# M344 register map
File version: 2.0.2.6
Registers are 32-bit, read-write, reset 0x0 unless marked. A register's access mark holds for its fields unless they carry their own. Offsets are from the block's base; [hi:lo] are bit positions; {n}, {i} and the like mark numbered series.

## TD0A — Timer D (Unit0)
Base 0x40158000
Same registers: TD0B 0x40359000
0x00 RUN wo — Timer Run Register (Unit0)
  [0] TDRUN
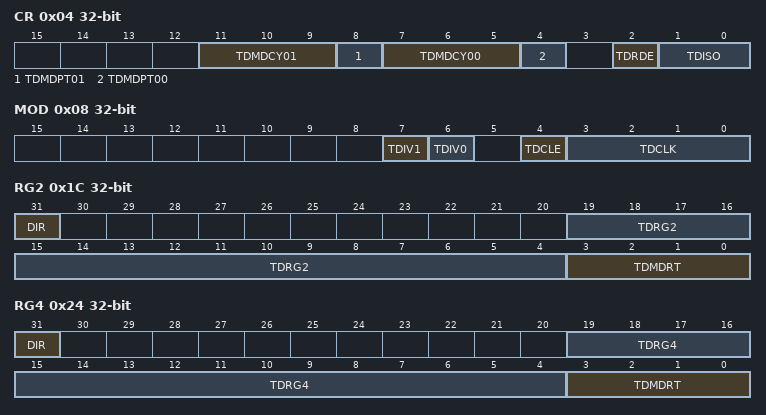
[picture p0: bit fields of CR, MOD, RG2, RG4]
0x04 CR — Timer Control Register (Unit0)
  [11:9] TDMDCY01, [8] TDMDPT01, [7:5] TDMDCY00, [4] TDMDPT00, [2] TDRDE, [1:0] TDISO
0x08 MOD — Timer Mode Register (Unit0)
  [7] TDIV1, [6] TDIV0, [4] TDCLE, [3:0] TDCLK
0x0C DMA — DMA Request Enable Register (Unit0)
  [0] DMAEN
0x14 RG0 — Timer Register0 (Unit0)
  [15:0] TDRG0
0x18 RG1 — Timer Register1 (Unit0)
  [15:0] TDRG1
0x1C RG2 — Timer Register2 (Unit0)
  [31] DIR, [19:4] TDRG2, [3:0] TDMDRT
0x20 RG3 — Timer Register3 (Unit0)
  [15:0] TDRG3
0x24 RG4 — Timer Register4 (Unit0)
  [31] DIR, [19:4] TDRG4, [3:0] TDMDRT
0x28 RG5 — Timer Register5 (Unit0)
  [16:1] TDRG5
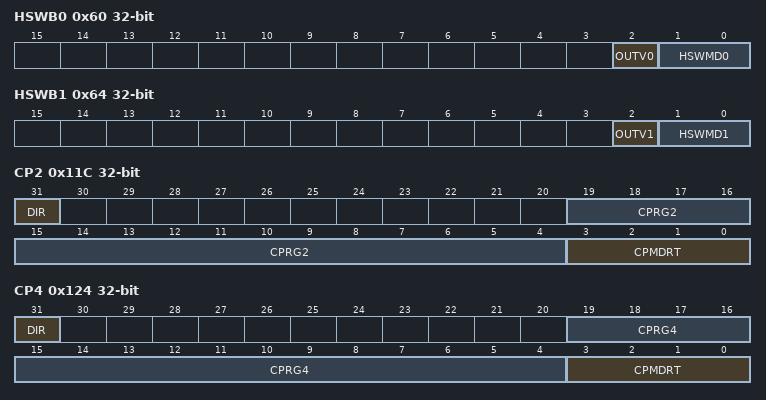
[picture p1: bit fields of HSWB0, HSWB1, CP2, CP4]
0x60 HSWB0 — H-SW Control Circuit Register Buffer0 (Unit0)
  [2] OUTV0, [1:0] HSWMD0
0x64 HSWB1 — H-SW Control Circuit Register Buffer1 (Unit0)
  [2] OUTV1, [1:0] HSWMD1
0x114 CP0 ro — Compare Register0 (Unit0)
  [15:0] CPRG0
0x118 CP1 ro — Compare Register1 (Unit0)
  [15:0] CPRG1
0x11C CP2 ro — Compare Register2 (Unit0)
  [31] DIR, [19:4] CPRG2, [3:0] CPMDRT
0x120 CP3 ro — Compare Register3 (Unit0)
  [15:0] CPRG3
0x124 CP4 ro — Compare Register4 (Unit0)
  [31] DIR, [19:4] CPRG4, [3:0] CPMDRT
0x128 CP5 ro — Compare Register5 (Unit0)
  [15:0] CPRG5
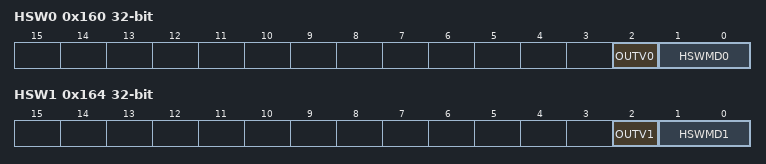
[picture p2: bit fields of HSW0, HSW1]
0x160 HSW0 ro — H-SW Control Circuit Register (Unit0)
  [2] OUTV0, [1:0] HSWMD0
0x164 HSW1 ro — H-SW Control Circuit Register (Unit0)
  [2] OUTV1, [1:0] HSWMD1

## TDA — Timer D common
Base 0x40158040
Same registers: TDB 0x40359040
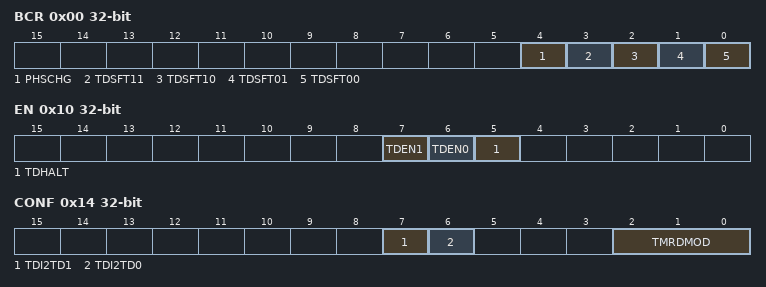
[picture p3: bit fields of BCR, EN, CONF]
0x00 BCR — Update Flag Setting Register
  [4] PHSCHG, [3] TDSFT11, [2] TDSFT10, [1] TDSFT01, [0] TDSFT00
0x10 EN — Timer Enable Register
  [7] TDEN1, [6] TDEN0, [5] TDHALT
0x14 CONF — Timer Configuration Register
  [7] TDI2TD1, [6] TDI2TD0, [2:0] TMRDMOD

## TD1A — Timer D (Unit1)
Base 0x4015802C
Same registers: TD1B 0x4035902C
0x00 RG0 — Timer Register0 (Unit1)
  [15:0] TDRG0
0x04 RG1 — Timer Register1 (Unit1)
  [15:0] TDRG1
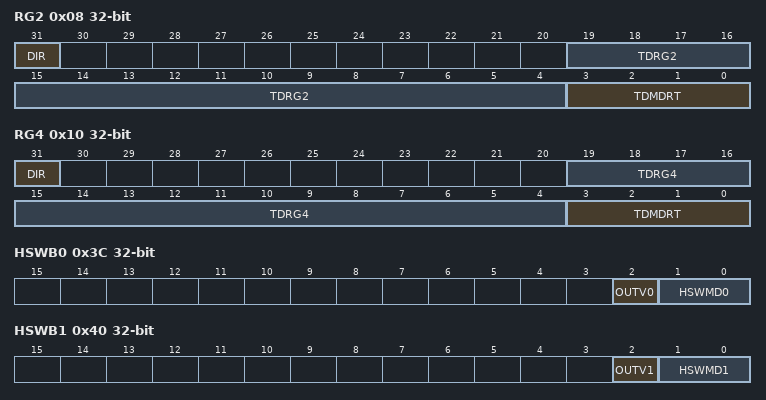
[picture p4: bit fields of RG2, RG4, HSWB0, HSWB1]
0x08 RG2 — Timer Register2 (Unit1)
  [31] DIR, [19:4] TDRG2, [3:0] TDMDRT
0x0C RG3 — Timer Register3 (Unit1)
  [15:0] TDRG3
0x10 RG4 — Timer Register4 (Unit1)
  [31] DIR, [19:4] TDRG4, [3:0] TDMDRT
0x3C HSWB0 — H-SW Control Circuit Register Buffer0 (Unit1)
  [2] OUTV0, [1:0] HSWMD0
0x40 HSWB1 — H-SW Control Circuit Register Buffer1 (Unit1)
  [2] OUTV1, [1:0] HSWMD1
0xD4 RUN wo — Timer Run Register (Unit1)
  [0] TDRUN
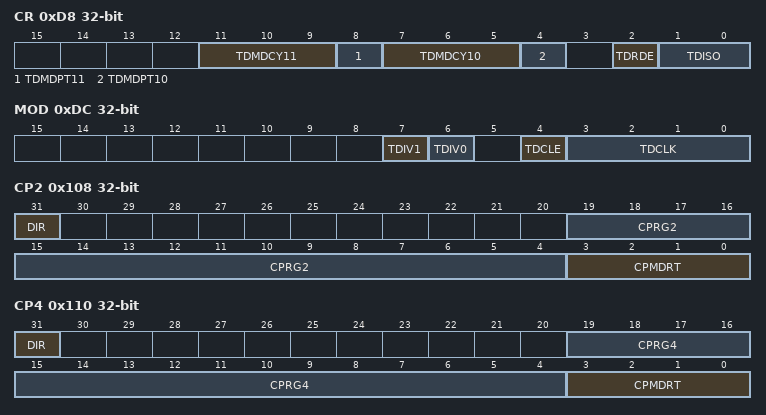
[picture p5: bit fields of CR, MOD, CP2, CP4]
0xD8 CR — Timer Control Register (Unit1)
  [11:9] TDMDCY11, [8] TDMDPT11, [7:5] TDMDCY10, [4] TDMDPT10, [2] TDRDE, [1:0] TDISO
0xDC MOD — Timer Mode Register (Unit1)
  [7] TDIV1, [6] TDIV0, [4] TDCLE, [3:0] TDCLK
0xE0 DMA — DMA Request Enable Register (Unit1)
  [0] DMAEN
0x100 CP0 ro — Compare Register0 (Unit1)
  [15:0] CPRG0
0x104 CP1 ro — Compare Register1 (Unit1)
  [15:0] CPRG1
0x108 CP2 ro — Compare Register2 (Unit1)
  [31] DIR, [19:4] CPRG2, [3:0] CPMDRT
0x10C CP3 ro — Compare Register3 (Unit1)
  [15:0] CPRG3
0x110 CP4 ro — Compare Register4 (Unit1)
  [31] DIR, [19:4] CPRG4, [3:0] CPMDRT
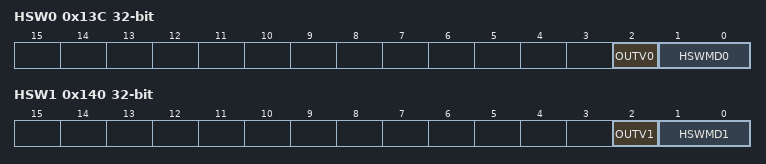
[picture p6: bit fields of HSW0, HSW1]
0x13C HSW0 ro — H-SW Control Circuit Register (Unit1)
  [2] OUTV0, [1:0] HSWMD0
0x140 HSW1 ro — H-SW Control Circuit Register (Unit1)
  [2] OUTV1, [1:0] HSWMD1

## EPHC0 — Enhannced two aspect pulse input counter (EPHC)
Base 0x40060000
Same registers: EPHC1 0x40061000, EPHC2 0x4007E000
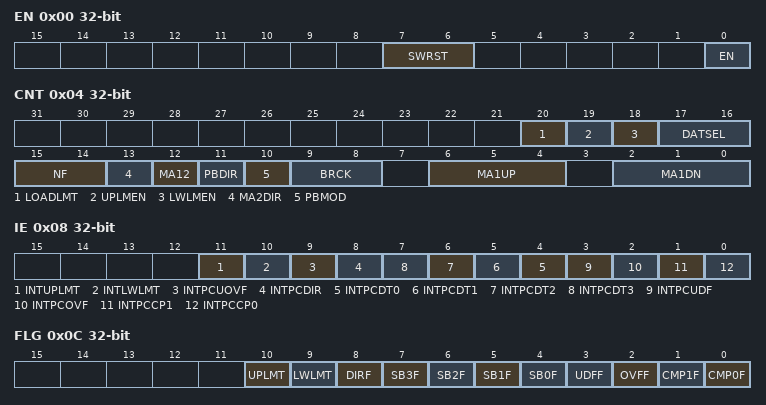
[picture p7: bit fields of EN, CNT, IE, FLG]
0x00 EN — EPHC Enable Register
  [7:6] SWRST wo, [0] EN
0x04 CNT — EPHC Control Register
  [20] LOADLMT wo, [19] UPLMEN, [18] LWLMEN, [17:16] DATSEL, [15:14] NF, [13] MA2DIR, [12] MA12, [11] PBDIR, [10] PBMOD, [9:8] BRCK, [6:4] MA1UP, [2:0] MA1DN
0x08 IE — EPHC Interrupt Enable Register
  [11] INTUPLMT, [10] INTLWLMT, [9] INTPCUOVF, [8] INTPCDIR, [n+4] INTPCDT{n} (n=0..3), [3] INTPCUDF, [2] INTPCOVF, [1] INTPCCP1, [0] INTPCCP0
0x0C FLG — EPHC Status Register
  [10] UPLMT, [9] LWLMT, [8] DIRF, [n+4] SB{n}F (n=0..3), [3] UDFF, [2] OVFF, [1] CMP1F, [0] CMP0F
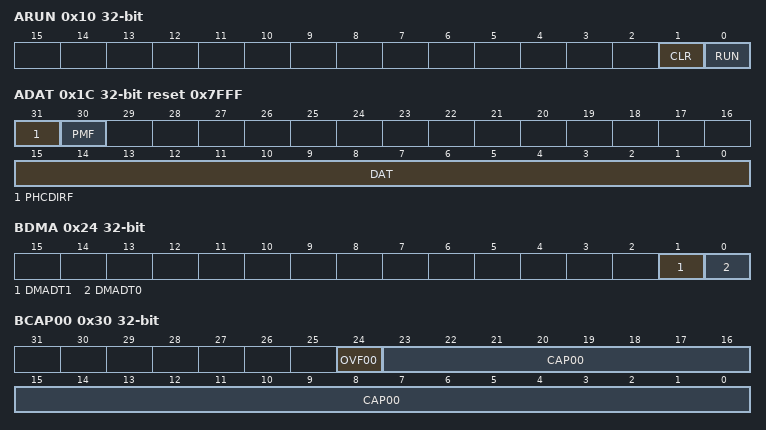
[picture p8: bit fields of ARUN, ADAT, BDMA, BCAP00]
0x10 ARUN — EPHC 16-bit Counter Run Register
  [1] CLR, [0] RUN
0x14 ACP0 — EPHC Pulse Counter Compare 0 Register
  [15:0] CMP0
0x18 ACP1 — EPHC Pulse Counter Compare 1 Register
  [15:0] CMP1
0x1C ADAT reset 0x7FFF — EPHC 16-bit Counter Read Register
  [31] PHCDIRF ro, [30] PMF ro, [15:0] DAT
0x20 BRUN — EPHC 24-bit Counter Run Register
  [0] T24RUN
0x24 BDMA — EPHC DMAE Request Enable Register
  [1] DMADT1, [0] DMADT0
0x28 BUC ro — EPHC 24-bit Counter Read Register
  [23:0] T24UCR
0x30 BCAP00 ro — EPHC Capture 00 Register
  [24] OVF00, [23:0] CAP00
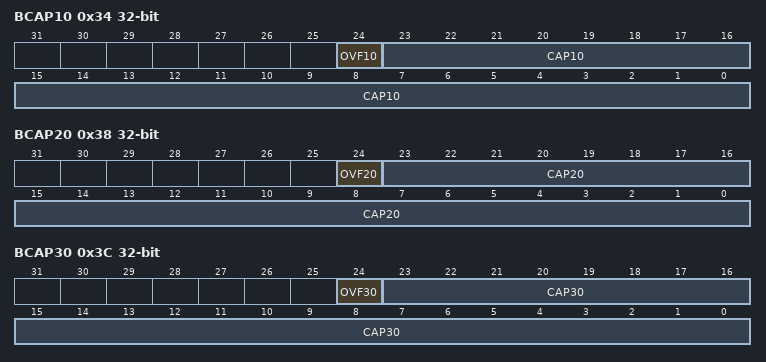
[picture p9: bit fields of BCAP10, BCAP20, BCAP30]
0x34 BCAP10 ro — EPHC Capture 10 Register
  [24] OVF10, [23:0] CAP10
0x38 BCAP20 ro — EPHC Capture 20 Register
  [24] OVF20, [23:0] CAP20
0x3C BCAP30 ro — EPHC Capture 30 Register
  [24] OVF30, [23:0] CAP30
{0x40+4i} B{i}DAT ro reset 0xFFFFFF (i=0..3) — EPHC Cycle {i} Register
  [23:0] B{i}DAT
0x50 BCDAT ro reset 0xFFFFFF — EPHC Cycle Common Register
  [23:0] BCDAT
{0x60+4i} B{i}PDT ro (i=0..3) — EPHC Phase DifferEPHCe {i} Register
  [23:0] B{i}PDT
0x70 UPLMT reset 0xFFFFFF — EPHC Upper Cycle Limit Value Register
  [23:0] UPLMT
0x74 LWLMT — EPHC Lower Cycle Limit Value Register
  [23:0] LWLMT

## EPHC0_PSC — Enhannced two aspect pulse input counter (EPHC) Mirror
Base 0x40175000
Registers as EPHC0, without EN, CNT, IE, FLG, ARUN, ACP0, ACP1, BRUN, BDMA, UPLMT, LWLMT.

## EPHC2_PSC — Enhannced two aspect pulse input counter (EPHC) Mirror
Base 0x4017C000
Same registers: EPHC1_PSC 0x40276000
Registers as EPHC0, without EN, CNT, IE, FLG, ARUN, ACP0, ACP1, BRUN, BDMA, UPLMT, LWLMT; these are added or differ:
{0x40+4i} B{i}DAT ro (i=0..3) — EPHC Cycle {i} Register
  [23:0] B{i}DAT
0x50 BCDAT ro — EPHC Cycle Common Register
  [23:0] BCDAT
